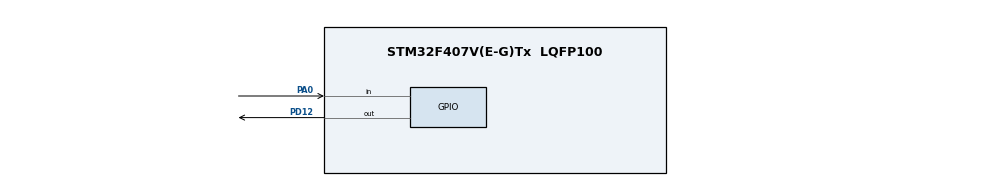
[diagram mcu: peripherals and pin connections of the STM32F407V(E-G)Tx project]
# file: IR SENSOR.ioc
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Mcu.Family=STM32F4
Mcu.Name=STM32F407V(E-G)Tx
Mcu.Package=LQFP100
NVIC.PriorityGroup=NVIC_PRIORITYGROUP_0
PA0-WKUP.Signal=GPIO_Input
PD12.Signal=GPIO_Output
ProjectManager.HeapSize=0x200
ProjectManager.StackSize=0x400
ProjectManager.TargetToolchain=STM32CubeIDE
RCC.48MHZClocksFreq_Value=48000000
RCC.AHBFreq_Value=168000000
RCC.APB1CLKDivider=RCC_HCLK_DIV4
RCC.APB1Freq_Value=42000000
RCC.APB1TimFreq_Value=84000000
RCC.APB2CLKDivider=RCC_HCLK_DIV2
RCC.APB2Freq_Value=84000000
RCC.APB2TimFreq_Value=168000000
RCC.CortexFreq_Value=168000000
RCC.HCLKFreq_Value=168000000
RCC.HSE_VALUE=8000000
RCC.HSI_VALUE=16000000
RCC.LSE_VALUE=32768
RCC.PLLM=8
RCC.PLLN=336
RCC.PLLQ=7
RCC.PLLSourceVirtual=RCC_PLLSOURCE_HSE
RCC.SYSCLKFreq_VALUE=168000000
RCC.SYSCLKSource=RCC_SYSCLKSOURCE_PLLCLK
RCC.VCOOutputFreq_Value=336000000
board=STM32F407G-DISC1

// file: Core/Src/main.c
/* USER CODE BEGIN Header */
/**
  ******************************************************************************
  * @file           : main.c
  * @brief          : Main program body
  ******************************************************************************
  * @attention
  *
  * Copyright (c) 2026 STMicroelectronics.
  * All rights reserved.
  *
  * This software is licensed under terms that can be found in the LICENSE file
  * in the root directory of this software component.
  * If no LICENSE file comes with this software, it is provided AS-IS.
  *
  ******************************************************************************
  */
/* USER CODE END Header */
#include "main.h"

/* USER CODE BEGIN Includes */
#include "stm32f4xx_hal.h"
#include <stdbool.h>

/* Function Prototypes */
void SystemClock_Config(void);
static void MX_GPIO_Init(void);

/* GPIO Config */
static void MX_GPIO_Init(void)
{
    __HAL_RCC_GPIOA_CLK_ENABLE();
    __HAL_RCC_GPIOD_CLK_ENABLE();

    GPIO_InitTypeDef GPIO_InitStruct = {0};

    /* IR Sensor Input Pin – PA0 */
    GPIO_InitStruct.Pin = GPIO_PIN_0;
    GPIO_InitStruct.Mode = GPIO_MODE_INPUT;
    GPIO_InitStruct.Pull = GPIO_NOPULL;
    HAL_GPIO_Init(GPIOA, &GPIO_InitStruct);

    /* LED Output Pin – PD12 */
    GPIO_InitStruct.Pin = GPIO_PIN_12;
    GPIO_InitStruct.Mode = GPIO_MODE_OUTPUT_PP;
    GPIO_InitStruct.Pull = GPIO_NOPULL;
    GPIO_InitStruct.Speed = GPIO_SPEED_FREQ_LOW;
    HAL_GPIO_Init(GPIOD, &GPIO_InitStruct);
}

/* Dummy clock config — use CubeMX to replace */
void SystemClock_Config(void)
{
    // Keep empty if you use generated system clock
}
/* USER CODE END Includes */

void SystemClock_Config(void);
static void MX_GPIO_Init(void);

int main(void)
{

  /* MCU Configuration--------------------------------------------------------*/

  /* Reset of all peripherals, Initializes the Flash interface and the Systick. */
  HAL_Init();

  /* Configure the system clock */
  SystemClock_Config();

  /* Initialize all configured peripherals */
  MX_GPIO_Init();

  /* Infinite loop */
while (1)
{

    /* USER CODE BEGIN 3 */
int ir_value = HAL_GPIO_ReadPin(GPIOA, GPIO_PIN_0);

if (ir_value == GPIO_PIN_RESET)
{
   HAL_GPIO_WritePin(GPIOD, GPIO_PIN_12, GPIO_PIN_SET);
}
else
{
   HAL_GPIO_WritePin(GPIOD, GPIO_PIN_12, GPIO_PIN_RESET);
}

HAL_Delay(20);
  /* USER CODE END 3 */
}
}

/* USER CODE END 4 */

void Error_Handler(void)
{
  __disable_irq();
  while (1)
  {
  }
}
